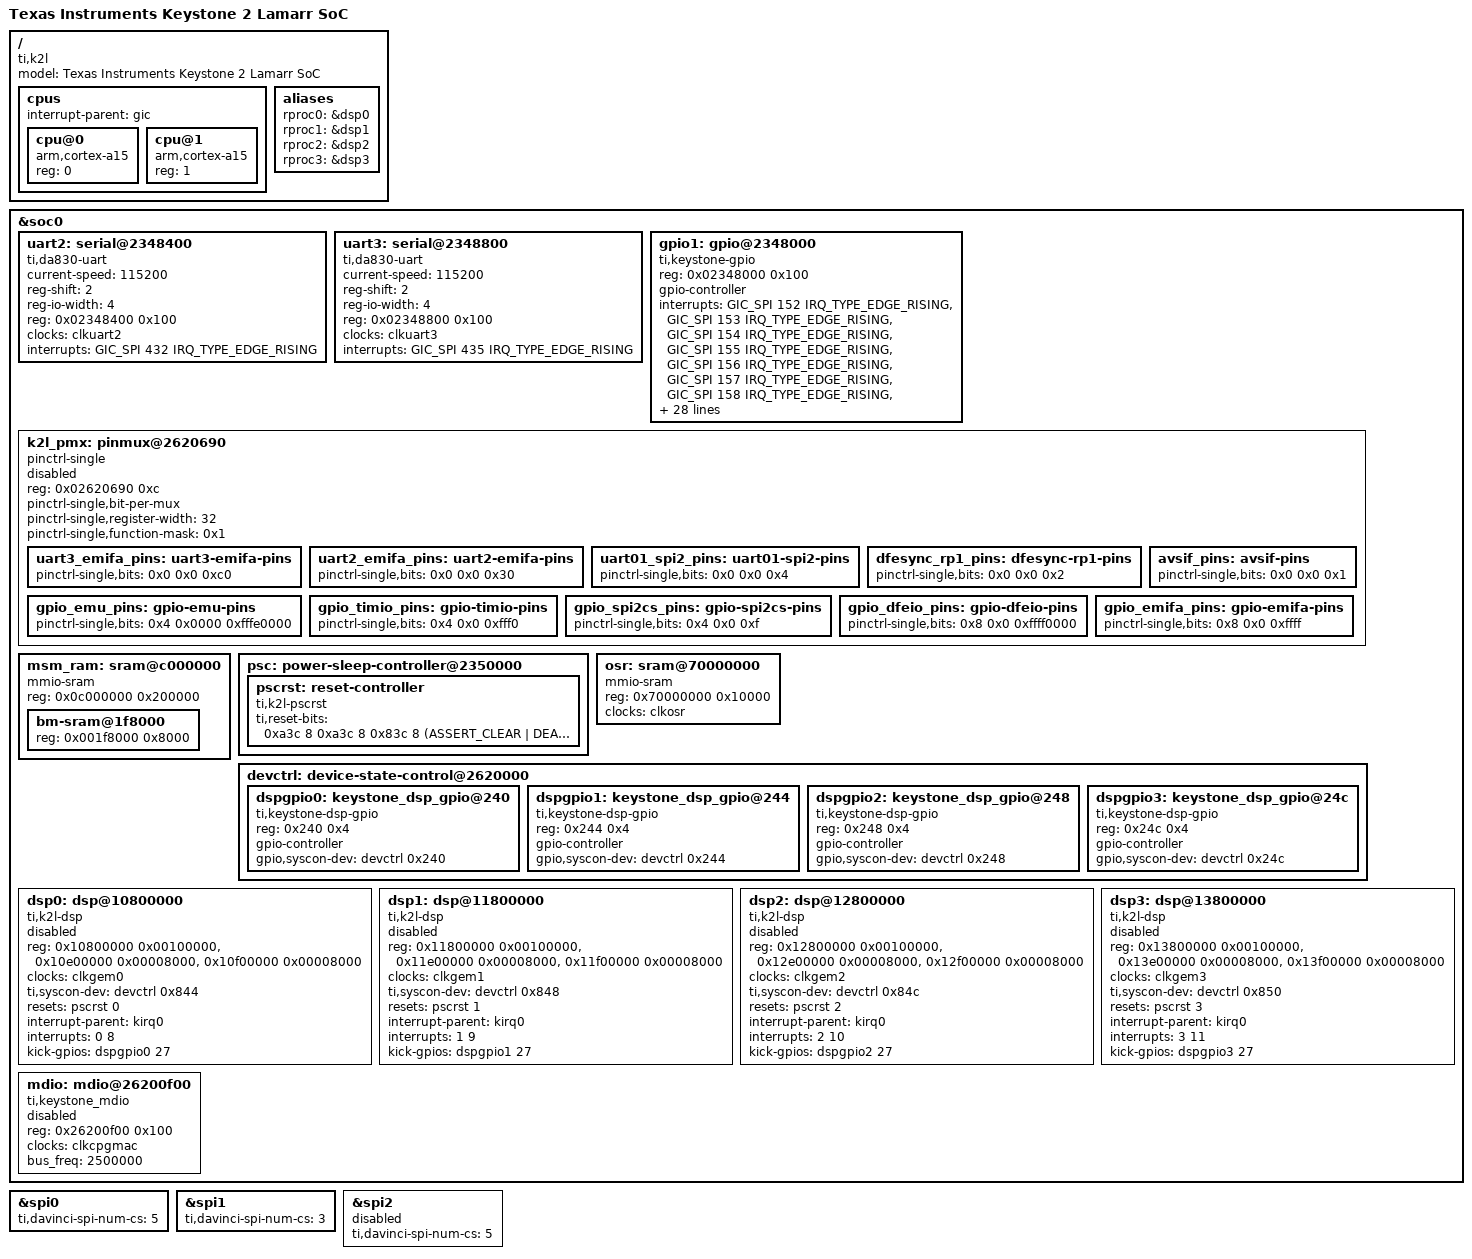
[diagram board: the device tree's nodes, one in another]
#include <dt-bindings/reset/ti-syscon.h>
/ {
	compatible = "ti,k2l", "ti,keystone";
	model = "Texas Instruments Keystone 2 Lamarr SoC";
	cpus {
		#address-cells = <1>;
		#size-cells = <0>;
		interrupt-parent = <&gic>;
		cpu@0 {
			compatible = "arm,cortex-a15";
			device_type = "cpu";
			reg = <0>;
		};
		cpu@1 {
			compatible = "arm,cortex-a15";
			device_type = "cpu";
			reg = <1>;
		};
	};
	aliases {
		rproc0 = &dsp0;
		rproc1 = &dsp1;
		rproc2 = &dsp2;
		rproc3 = &dsp3;
	};
};
&soc0 {
		/include/ "keystone-k2l-clocks.dtsi"
		uart2: serial@2348400 {
			compatible = "ti,da830-uart", "ns16550a";
			current-speed = <115200>;
			reg-shift = <2>;
			reg-io-width = <4>;
			reg = <0x02348400 0x100>;
			clocks = <&clkuart2>;
			interrupts = <GIC_SPI 432 IRQ_TYPE_EDGE_RISING>;
		};
		uart3:	serial@2348800 {
			compatible = "ti,da830-uart", "ns16550a";
			current-speed = <115200>;
			reg-shift = <2>;
			reg-io-width = <4>;
			reg = <0x02348800 0x100>;
			clocks = <&clkuart3>;
			interrupts = <GIC_SPI 435 IRQ_TYPE_EDGE_RISING>;
		};
		gpio1: gpio@2348000 {
			compatible = "ti,keystone-gpio";
			reg = <0x02348000 0x100>;
			gpio-controller;
			#gpio-cells = <2>;
			interrupts = <GIC_SPI 152 IRQ_TYPE_EDGE_RISING>,
					<GIC_SPI 153 IRQ_TYPE_EDGE_RISING>,
					<GIC_SPI 154 IRQ_TYPE_EDGE_RISING>,
					<GIC_SPI 155 IRQ_TYPE_EDGE_RISING>,
					<GIC_SPI 156 IRQ_TYPE_EDGE_RISING>,
					<GIC_SPI 157 IRQ_TYPE_EDGE_RISING>,
					<GIC_SPI 158 IRQ_TYPE_EDGE_RISING>,
					<GIC_SPI 159 IRQ_TYPE_EDGE_RISING>,
					<GIC_SPI 160 IRQ_TYPE_EDGE_RISING>,
					<GIC_SPI 161 IRQ_TYPE_EDGE_RISING>,
					<GIC_SPI 162 IRQ_TYPE_EDGE_RISING>,
					<GIC_SPI 163 IRQ_TYPE_EDGE_RISING>,
					<GIC_SPI 164 IRQ_TYPE_EDGE_RISING>,
					<GIC_SPI 165 IRQ_TYPE_EDGE_RISING>,
					<GIC_SPI 166 IRQ_TYPE_EDGE_RISING>,
					<GIC_SPI 167 IRQ_TYPE_EDGE_RISING>,
					<GIC_SPI 168 IRQ_TYPE_EDGE_RISING>,
					<GIC_SPI 169 IRQ_TYPE_EDGE_RISING>,
					<GIC_SPI 170 IRQ_TYPE_EDGE_RISING>,
					<GIC_SPI 171 IRQ_TYPE_EDGE_RISING>,
					<GIC_SPI 172 IRQ_TYPE_EDGE_RISING>,
					<GIC_SPI 173 IRQ_TYPE_EDGE_RISING>,
					<GIC_SPI 174 IRQ_TYPE_EDGE_RISING>,
					<GIC_SPI 175 IRQ_TYPE_EDGE_RISING>,
					<GIC_SPI 176 IRQ_TYPE_EDGE_RISING>,
					<GIC_SPI 401 IRQ_TYPE_EDGE_RISING>,
					<GIC_SPI 402 IRQ_TYPE_EDGE_RISING>,
					<GIC_SPI 403 IRQ_TYPE_EDGE_RISING>,
					<GIC_SPI 404 IRQ_TYPE_EDGE_RISING>,
					<GIC_SPI 405 IRQ_TYPE_EDGE_RISING>,
					<GIC_SPI 406 IRQ_TYPE_EDGE_RISING>,
					<GIC_SPI 407 IRQ_TYPE_EDGE_RISING>;
			clocks = <&clkgpio>;
			clock-names = "gpio";
			ti,ngpio = <32>;
			ti,davinci-gpio-unbanked = <32>;
		};
		k2l_pmx: pinmux@2620690 {
			compatible = "pinctrl-single";
			reg = <0x02620690 0xc>;
			#address-cells = <1>;
			#size-cells = <0>;
			#pinctrl-cells = <2>;
			pinctrl-single,bit-per-mux;
			pinctrl-single,register-width = <32>;
			pinctrl-single,function-mask = <0x1>;
			status = "disabled";
			uart3_emifa_pins: uart3-emifa-pins {
				pinctrl-single,bits = <
					0x0 0x0  0xc0
				>;
			};
			uart2_emifa_pins: uart2-emifa-pins {
			pinctrl-single,bits = <
					0x0 0x0  0x30
				>;
			};
			uart01_spi2_pins: uart01-spi2-pins {
				pinctrl-single,bits = <
					0x0 0x0 0x4
				>;
			};
			dfesync_rp1_pins: dfesync-rp1-pins {
				pinctrl-single,bits = <
					0x0 0x0 0x2
				>;
			};
			avsif_pins: avsif-pins {
				pinctrl-single,bits = <
					0x0 0x0 0x1
				>;
			};
			gpio_emu_pins: gpio-emu-pins {
				pinctrl-single,bits = <
					0x4 0x0000 0xfffe0000
				>;
			};
			gpio_timio_pins: gpio-timio-pins {
				pinctrl-single,bits = <
					0x4 0x0 0xfff0
				>;
			};
			gpio_spi2cs_pins: gpio-spi2cs-pins {
				pinctrl-single,bits = <
					0x4 0x0 0xf
				>;
			};
			gpio_dfeio_pins: gpio-dfeio-pins {
				pinctrl-single,bits = <
					0x8 0x0 0xffff0000
				>;
			};
			gpio_emifa_pins: gpio-emifa-pins {
				pinctrl-single,bits = <
					0x8 0x0 0xffff
				>;
			};
		};
		msm_ram: sram@c000000 {
			compatible = "mmio-sram";
			reg = <0x0c000000 0x200000>;
			ranges = <0x0 0x0c000000 0x200000>;
			#address-cells = <1>;
			#size-cells = <1>;
			bm-sram@1f8000 {
				reg = <0x001f8000 0x8000>;
			};
		};
		psc: power-sleep-controller@2350000 {
			pscrst: reset-controller {
				compatible = "ti,k2l-pscrst", "ti,syscon-reset";
				#reset-cells = <1>;
				ti,reset-bits = <
					0xa3c 8 0xa3c 8 0x83c 8 (ASSERT_CLEAR | DEASSERT_SET | STATUS_CLEAR)  
					0xa40 8 0xa40 8 0x840 8 (ASSERT_CLEAR | DEASSERT_SET | STATUS_CLEAR)  
					0xa44 8 0xa44 8 0x844 8 (ASSERT_CLEAR | DEASSERT_SET | STATUS_CLEAR)  
					0xa48 8 0xa48 8 0x848 8 (ASSERT_CLEAR | DEASSERT_SET | STATUS_CLEAR)  
				>;
			};
		};
		osr: sram@70000000 {
			compatible = "mmio-sram";
			reg = <0x70000000 0x10000>;
			#address-cells = <1>;
			#size-cells = <1>;
			clocks = <&clkosr>;
		};
		devctrl: device-state-control@2620000 {
			dspgpio0: keystone_dsp_gpio@240 {
				compatible = "ti,keystone-dsp-gpio";
				reg = <0x240 0x4>;
				gpio-controller;
				#gpio-cells = <2>;
				gpio,syscon-dev = <&devctrl 0x240>;
			};
			dspgpio1: keystone_dsp_gpio@244 {
				compatible = "ti,keystone-dsp-gpio";
				reg = <0x244 0x4>;
				gpio-controller;
				#gpio-cells = <2>;
				gpio,syscon-dev = <&devctrl 0x244>;
			};
			dspgpio2: keystone_dsp_gpio@248 {
				compatible = "ti,keystone-dsp-gpio";
				reg = <0x248 0x4>;
				gpio-controller;
				#gpio-cells = <2>;
				gpio,syscon-dev = <&devctrl 0x248>;
			};
			dspgpio3: keystone_dsp_gpio@24c {
				compatible = "ti,keystone-dsp-gpio";
				reg = <0x24c 0x4>;
				gpio-controller;
				#gpio-cells = <2>;
				gpio,syscon-dev = <&devctrl 0x24c>;
			};
		};
		dsp0: dsp@10800000 {
			compatible = "ti,k2l-dsp";
			reg = <0x10800000 0x00100000>,
			      <0x10e00000 0x00008000>,
			      <0x10f00000 0x00008000>;
			reg-names = "l2sram", "l1pram", "l1dram";
			clocks = <&clkgem0>;
			ti,syscon-dev = <&devctrl 0x844>;
			resets = <&pscrst 0>;
			interrupt-parent = <&kirq0>;
			interrupts = <0 8>;
			interrupt-names = "vring", "exception";
			kick-gpios = <&dspgpio0 27 0>;
			status = "disabled";
		};
		dsp1: dsp@11800000 {
			compatible = "ti,k2l-dsp";
			reg = <0x11800000 0x00100000>,
			      <0x11e00000 0x00008000>,
			      <0x11f00000 0x00008000>;
			reg-names = "l2sram", "l1pram", "l1dram";
			clocks = <&clkgem1>;
			ti,syscon-dev = <&devctrl 0x848>;
			resets = <&pscrst 1>;
			interrupt-parent = <&kirq0>;
			interrupts = <1 9>;
			interrupt-names = "vring", "exception";
			kick-gpios = <&dspgpio1 27 0>;
			status = "disabled";
		};
		dsp2: dsp@12800000 {
			compatible = "ti,k2l-dsp";
			reg = <0x12800000 0x00100000>,
			      <0x12e00000 0x00008000>,
			      <0x12f00000 0x00008000>;
			reg-names = "l2sram", "l1pram", "l1dram";
			clocks = <&clkgem2>;
			ti,syscon-dev = <&devctrl 0x84c>;
			resets = <&pscrst 2>;
			interrupt-parent = <&kirq0>;
			interrupts = <2 10>;
			interrupt-names = "vring", "exception";
			kick-gpios = <&dspgpio2 27 0>;
			status = "disabled";
		};
		dsp3: dsp@13800000 {
			compatible = "ti,k2l-dsp";
			reg = <0x13800000 0x00100000>,
			      <0x13e00000 0x00008000>,
			      <0x13f00000 0x00008000>;
			reg-names = "l2sram", "l1pram", "l1dram";
			clocks = <&clkgem3>;
			ti,syscon-dev = <&devctrl 0x850>;
			resets = <&pscrst 3>;
			interrupt-parent = <&kirq0>;
			interrupts = <3 11>;
			interrupt-names = "vring", "exception";
			kick-gpios = <&dspgpio3 27 0>;
			status = "disabled";
		};
		mdio: mdio@26200f00 {
			compatible = "ti,keystone_mdio", "ti,davinci_mdio";
			#address-cells = <1>;
			#size-cells = <0>;
			reg = <0x26200f00 0x100>;
			status = "disabled";
			clocks = <&clkcpgmac>;
			clock-names = "fck";
			bus_freq = <2500000>;
		};
		/include/ "keystone-k2l-netcp.dtsi"
};
&spi0 {
       ti,davinci-spi-num-cs = <5>;
};
&spi1 {
       ti,davinci-spi-num-cs = <3>;
};
&spi2 {
       ti,davinci-spi-num-cs = <5>;
       status = "disabled";
};
